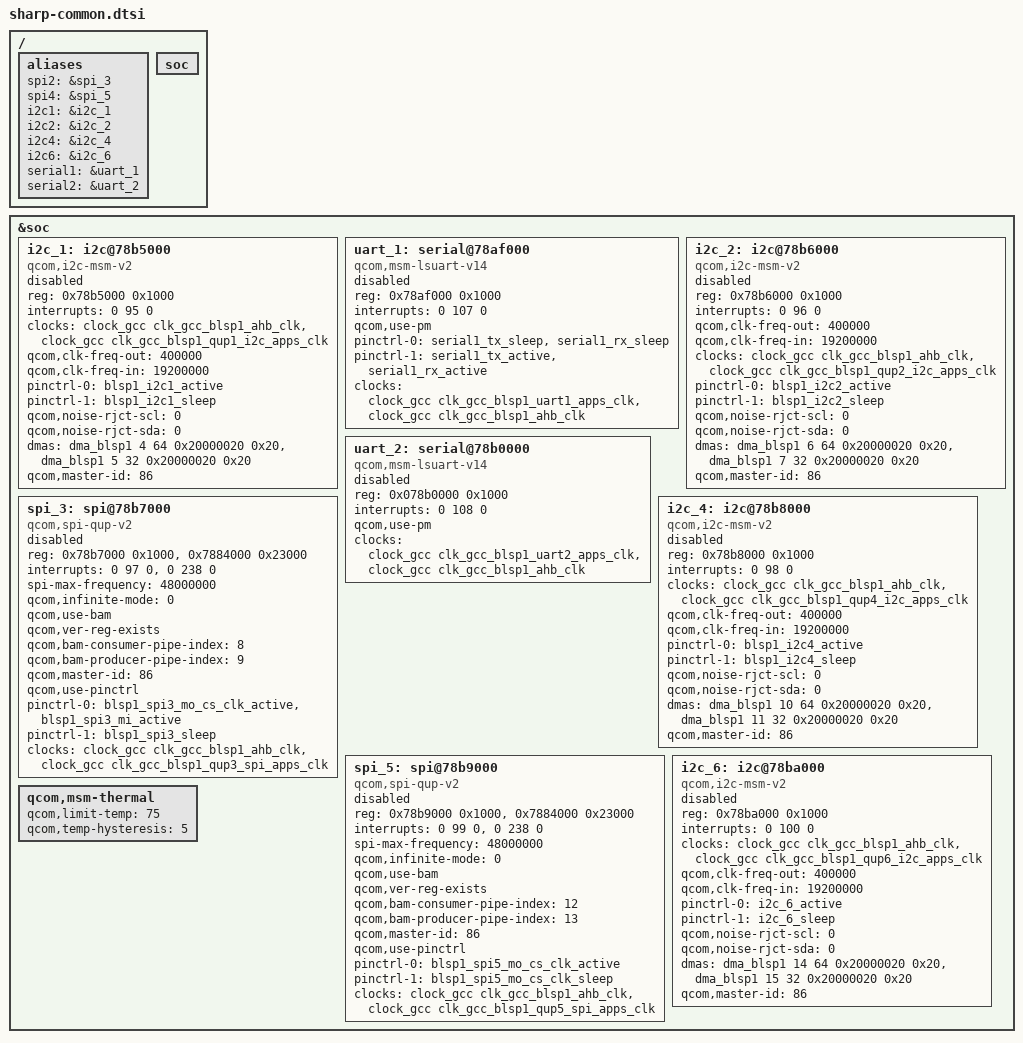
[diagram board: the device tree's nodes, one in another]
/* Copyright (c) 2015, The Linux Foundation. All rights reserved.
 *
 * This program is free software; you can redistribute it and/or modify
 * it under the terms of the GNU General Public License version 2 and
 * only version 2 as published by the Free Software Foundation.
 *
 * This program is distributed in the hope that it will be useful,
 * but WITHOUT ANY WARRANTY; without even the implied warranty of
 * MERCHANTABILITY or FITNESS FOR A PARTICULAR PURPOSE.  See the
 * GNU General Public License for more details.
 */

#include "sharp-pinctrl.dtsi"
#include "sharp-common-sdcc.dtsi"

/*----------------------------------------*/
/* Delete Qualcomm settings.              */
/*----------------------------------------*/
/ {
	aliases {
		spi2 = &spi_3;
		spi4 = &spi_5;

		i2c1 = &i2c_1;
		i2c2 = &i2c_2;
		i2c4 = &i2c_4;
		i2c6 = &i2c_6;

		serial1 = &uart_1;
		serial2 = &uart_2;
	};
	soc {
		/delete-node/ i2c@78b5000;
		/delete-node/ i2c@78b6000;
		/delete-node/ i2c@78b7000;
		/delete-node/ i2c@78b8000;
		/delete-node/ i2c@78b9000;
		/delete-node/ serial@78af000;
		/delete-node/ serial@78b0000;
		/delete-node/ spi@78ba000;
	};

};

/*----------------------------------------*/
/* Add SHARP settings.                    */
/*----------------------------------------*/
&soc {
    /*****************************************/
	/*  BLSP1                                */
	/*****************************************/
	/*---------------------*/
	/* BLSP1 QUP0(BLSP#1)  */
	/*---------------------*/
	i2c_1: i2c@78b5000 {
		compatible = "qcom,i2c-msm-v2";
		#address-cells = <1>;
		#size-cells = <0>;
		reg-names = "qup_phys_addr";
		reg = <0x78b5000 0x1000>;
		interrupt-names = "qup_irq";
		interrupts = <0 95 0>;
		clocks = <&clock_gcc clk_gcc_blsp1_ahb_clk>,
		         <&clock_gcc clk_gcc_blsp1_qup1_i2c_apps_clk>;
		clock-names = "iface_clk", "core_clk";
		qcom,clk-freq-out = <400000>;
		qcom,clk-freq-in  = <19200000>;
		pinctrl-names = "i2c_active", "i2c_sleep";
		pinctrl-0 = <&blsp1_i2c1_active>;
		pinctrl-1 = <&blsp1_i2c1_sleep>;
		qcom,noise-rjct-scl = <0>;
		qcom,noise-rjct-sda = <0>;
		dmas = <&dma_blsp1 4 64 0x20000020 0x20>,
			<&dma_blsp1 5  32 0x20000020 0x20>;
		dma-names = "tx", "rx";
		qcom,master-id = <86>;
		status = "disabled";
	};

	uart_1: serial@78af000 {
		compatible = "qcom,msm-lsuart-v14";
		reg = <0x78af000 0x1000>;
		interrupts = <0 107 0>;
		qcom,use-pm;
		pinctrl-names = "sleep", "default";
		pinctrl-0 = <&serial1_tx_sleep &serial1_rx_sleep>;
		pinctrl-1 = <&serial1_tx_active &serial1_rx_active>;
		clock-names = "core_clk", "iface_clk";
		clocks = <&clock_gcc clk_gcc_blsp1_uart1_apps_clk>,
			<&clock_gcc clk_gcc_blsp1_ahb_clk>;
		status = "disabled";
	};

	/*---------------------*/
	/* BLSP1 QUP1(BLSP#2)  */
	/*---------------------*/
	i2c_2: i2c@78b6000 { /* BLSP1 QUP2 */
		compatible = "qcom,i2c-msm-v2";
		#address-cells = <1>;
		#size-cells = <0>;
		reg-names = "qup_phys_addr";
		reg = <0x78b6000 0x1000>;
		interrupt-names = "qup_irq";
		interrupts = <0 96 0>;
		qcom,clk-freq-out = <400000>;
		qcom,clk-freq-in  = <19200000>;
		clock-names = "iface_clk", "core_clk";
		clocks = <&clock_gcc clk_gcc_blsp1_ahb_clk>,
			 <&clock_gcc clk_gcc_blsp1_qup2_i2c_apps_clk>;

		pinctrl-names = "i2c_active", "i2c_sleep";
		pinctrl-0 = <&blsp1_i2c2_active>;
		pinctrl-1 = <&blsp1_i2c2_sleep>;
		qcom,noise-rjct-scl = <0>;
		qcom,noise-rjct-sda = <0>;
		dmas = <&dma_blsp1 6 64 0x20000020 0x20>,
			<&dma_blsp1 7 32 0x20000020 0x20>;
		dma-names = "tx", "rx";
		qcom,master-id = <86>;
		status = "disabled";
	};

	uart_2: serial@78b0000 {
		compatible = "qcom,msm-lsuart-v14";
		reg = <0x078b0000 0x1000>;
		interrupts = <0 108 0>;
		qcom,use-pm;
//		pinctrl-names = "sleep", "default";
//		pinctrl-names = "sleep", "active";
//		pinctrl-0 = <&serial2_tx_rx_sleep>;
//		pinctrl-1 = <&serial2_tx_rx_active>;
		clock-names = "core_clk", "iface_clk";
		clocks = <&clock_gcc clk_gcc_blsp1_uart2_apps_clk>,
			<&clock_gcc clk_gcc_blsp1_ahb_clk>;
		status = "disabled";
	};

	/*---------------------*/
	/* BLSP1 QUP2(BLSP#3)  */
	/*---------------------*/
	spi_3: spi@78b7000 {
		compatible = "qcom,spi-qup-v2";
		#address-cells = <1>;
		#size-cells = <0>;
		reg-names = "spi_physical", "spi_bam_physical";
		reg = <0x78b7000 0x1000>,
			<0x7884000 0x23000>;
		interrupt-names = "spi_irq", "spi_bam_irq";
		interrupts = <0 97 0>, <0 238 0>;
		spi-max-frequency = <48000000>;

		qcom,infinite-mode = <0>;
		qcom,use-bam;
		qcom,ver-reg-exists;
		qcom,bam-consumer-pipe-index = <8>;
		qcom,bam-producer-pipe-index = <9>;
		qcom,master-id = <86>;
		qcom,use-pinctrl;
		pinctrl-names = "spi_default", "spi_sleep";
		pinctrl-0 = <&blsp1_spi3_mo_cs_clk_active &blsp1_spi3_mi_active>;
		pinctrl-1 = <&blsp1_spi3_sleep>;

		clock-names = "iface_clk", "core_clk";
		clocks = <&clock_gcc clk_gcc_blsp1_ahb_clk>,
			 <&clock_gcc clk_gcc_blsp1_qup3_spi_apps_clk>;
		status = "disabled";
	};

	/*---------------------*/
	/* BLSP1 QUP3(BLSP#4)  */
	/*---------------------*/
	i2c_4: i2c@78b8000 { /* BLSP1 QUP4 */
		compatible = "qcom,i2c-msm-v2";
		#address-cells = <1>;
		#size-cells = <0>;
		reg-names = "qup_phys_addr";
		reg = <0x78b8000 0x1000>;
		interrupt-names = "qup_irq";
		interrupts = <0 98 0>;
		clocks = <&clock_gcc clk_gcc_blsp1_ahb_clk>,
			 <&clock_gcc clk_gcc_blsp1_qup4_i2c_apps_clk>;
		clock-names = "iface_clk", "core_clk";
		qcom,clk-freq-out = <400000>;
		qcom,clk-freq-in  = <19200000>;
		pinctrl-names = "i2c_active", "i2c_sleep";
		pinctrl-0 = <&blsp1_i2c4_active>;
		pinctrl-1 = <&blsp1_i2c4_sleep>;
		qcom,noise-rjct-scl = <0>;
		qcom,noise-rjct-sda = <0>;
		dmas = <&dma_blsp1 10 64 0x20000020 0x20>,
			<&dma_blsp1 11 32 0x20000020 0x20>;
		dma-names = "tx", "rx";
		qcom,master-id = <86>;
		status = "disabled";
	};

	/*---------------------*/
	/* BLSP1 QUP4(BLSP#5)  */
	/*---------------------*/
	spi_5: spi@78b9000 {
		compatible = "qcom,spi-qup-v2";
		#address-cells = <1>;
		#size-cells = <0>;
		reg-names = "spi_physical", "spi_bam_physical";
		reg = <0x78b9000 0x1000>,
			<0x7884000 0x23000>;
		interrupt-names = "spi_irq", "spi_bam_irq";
		interrupts = <0 99 0>, <0 238 0>;
		spi-max-frequency = <48000000>;

		qcom,infinite-mode = <0>;
		qcom,use-bam;
		qcom,ver-reg-exists;
		qcom,bam-consumer-pipe-index = <12>;
		qcom,bam-producer-pipe-index = <13>;
		qcom,master-id = <86>;
		qcom,use-pinctrl;
		pinctrl-names = "spi_default", "spi_sleep";
		pinctrl-0 = <&blsp1_spi5_mo_cs_clk_active>;
		pinctrl-1 = <&blsp1_spi5_mo_cs_clk_sleep>;

		clock-names = "iface_clk", "core_clk";
		clocks = <&clock_gcc clk_gcc_blsp1_ahb_clk>,
			 <&clock_gcc clk_gcc_blsp1_qup5_spi_apps_clk>;
		status = "disabled";
	};

	/*---------------------*/
	/* BLSP1 QUP5(BLSP#6)  */
	/*---------------------*/
	i2c_6: i2c@78ba000 {
		compatible = "qcom,i2c-msm-v2";
		#address-cells = <1>;
		#size-cells = <0>;
		reg-names = "qup_phys_addr";
		reg = <0x78ba000 0x1000>;
		interrupt-names = "qup_irq";
		interrupts = <0 100 0>;
		clocks = <&clock_gcc clk_gcc_blsp1_ahb_clk>,
			 <&clock_gcc clk_gcc_blsp1_qup6_i2c_apps_clk>;
		clock-names = "iface_clk", "core_clk";
		qcom,clk-freq-out = <400000>;
		qcom,clk-freq-in  = <19200000>;
		pinctrl-names = "i2c_active", "i2c_sleep";
		pinctrl-0 = <&i2c_6_active>;
		pinctrl-1 = <&i2c_6_sleep>;
		qcom,noise-rjct-scl = <0>;
		qcom,noise-rjct-sda = <0>;
		dmas = <&dma_blsp1 14 64 0x20000020 0x20>,
			<&dma_blsp1 15 32 0x20000020 0x20>;
		qcom,master-id = <86>;
		dma-names = "tx", "rx";
		status = "disabled";
	};
	/*----------------------------------------------*/
	/* msm_thermal cpu_clock restriction thresholds */
	/*----------------------------------------------*/
	qcom,msm-thermal {
		qcom,limit-temp = <75>;
		qcom,temp-hysteresis = <5>;
	};
};

#include "sharp-8909-irda.dtsi"
